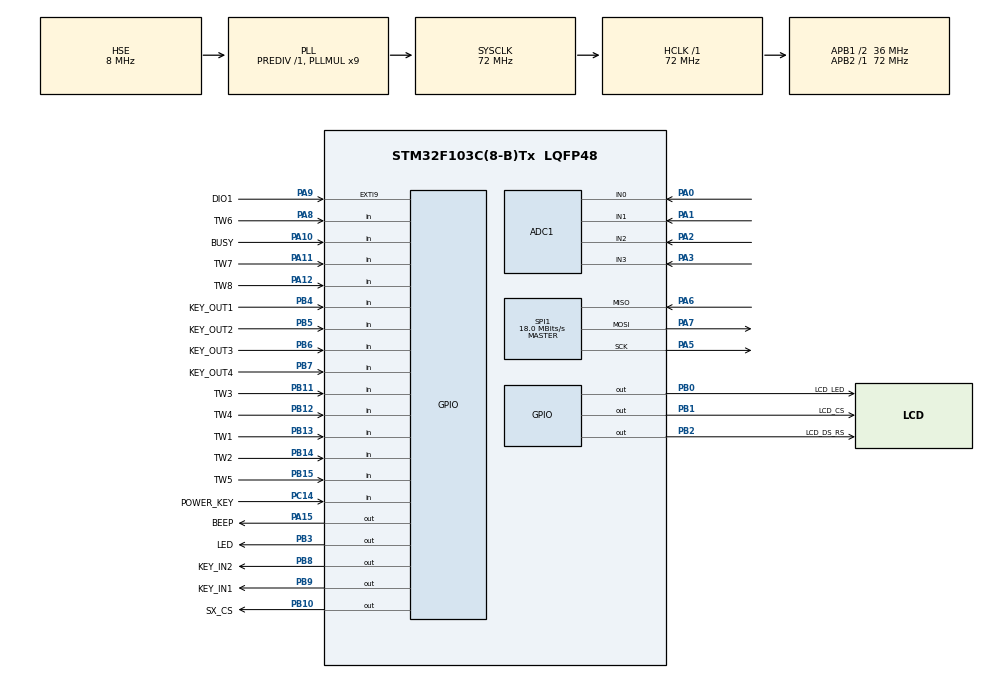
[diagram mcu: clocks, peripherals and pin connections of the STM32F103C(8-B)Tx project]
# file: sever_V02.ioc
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ADC1.Channel-1\#ChannelRegularConversion=ADC_CHANNEL_1
ADC1.Channel-2\#ChannelRegularConversion=ADC_CHANNEL_2
ADC1.Channel-3\#ChannelRegularConversion=ADC_CHANNEL_3
ADC1.ContinuousConvMode=ENABLE
ADC1.NbrOfConversion=4
ADC1.NbrOfConversionFlag=1
ADC1.Rank-1\#ChannelRegularConversion=2
ADC1.Rank-2\#ChannelRegularConversion=3
ADC1.Rank-3\#ChannelRegularConversion=4
ADC1.SamplingTime-0\#ChannelRegularConversion=ADC_SAMPLETIME_239CYCLES_5
ADC1.SamplingTime-1\#ChannelRegularConversion=ADC_SAMPLETIME_239CYCLES_5
ADC1.SamplingTime-2\#ChannelRegularConversion=ADC_SAMPLETIME_239CYCLES_5
ADC1.SamplingTime-3\#ChannelRegularConversion=ADC_SAMPLETIME_239CYCLES_5
ADC1.master=1
Dma.ADC1.0.Direction=DMA_PERIPH_TO_MEMORY
Dma.ADC1.0.Instance=DMA1_Channel1
Dma.ADC1.0.MemDataAlignment=DMA_MDATAALIGN_HALFWORD
Dma.ADC1.0.MemInc=DMA_MINC_ENABLE
Dma.ADC1.0.Mode=DMA_CIRCULAR
Dma.ADC1.0.PeriphDataAlignment=DMA_PDATAALIGN_HALFWORD
Dma.ADC1.0.PeriphInc=DMA_PINC_DISABLE
Dma.ADC1.0.Priority=DMA_PRIORITY_LOW
Dma.Request0=ADC1
FREERTOS.INCLUDE_uxTaskGetStackHighWaterMark=1
FREERTOS.INCLUDE_vTaskDelayUntil=1
FREERTOS.Tasks01=defaultTask,0,128,StartDefaultTask,Default,NULL,Dynamic,NULL,NULL;START_TASK,-3,128,startTask,Default,NULL,Dynamic,NULL,NULL
FREERTOS.configTOTAL_HEAP_SIZE=8192
FREERTOS.configUSE_COUNTING_SEMAPHORES=1
FREERTOS.configUSE_RECURSIVE_MUTEXES=1
Mcu.Family=STM32F1
Mcu.Name=STM32F103C(8-B)Tx
Mcu.Package=LQFP48
NVIC.DMA1_Channel1_IRQn=true\:5\:0\:false\:false\:true\:true\:false\:true\:true
NVIC.EXTI9_5_IRQn=true\:5\:0\:false\:false\:true\:true\:true\:true\:true
NVIC.PriorityGroup=NVIC_PRIORITYGROUP_4
NVIC.TIM3_IRQn=true\:15\:0\:false\:false\:true\:false\:false\:true\:true
NVIC.TIM4_IRQn=true\:5\:0\:false\:false\:true\:true\:true\:true\:true
NVIC.TimeBase=TIM3_IRQn
NVIC.TimeBaseIP=TIM3
PA0-WKUP.Signal=ADCx_IN0
PA1.Signal=ADCx_IN1
PA10.GPIO_Label=BUSY
PA10.GPIO_PuPd=GPIO_PULLUP
PA10.Signal=GPIO_Input
PA11.GPIO_Label=TW7
PA11.GPIO_PuPd=GPIO_PULLDOWN
PA11.Signal=GPIO_Input
PA12.GPIO_Label=TW8
PA12.GPIO_PuPd=GPIO_PULLDOWN
PA12.Signal=GPIO_Input
PA13.Mode=Serial_Wire
PA13.Signal=SYS_JTMS-SWDIO
PA14.Mode=Serial_Wire
PA14.Signal=SYS_JTCK-SWCLK
PA15.GPIO_Label=BEEP
PA15.Signal=GPIO_Output
PA2.Signal=ADCx_IN2
PA3.Signal=ADCx_IN3
PA5.Mode=Full_Duplex_Master
PA5.Signal=SPI1_SCK
PA6.Mode=Full_Duplex_Master
PA6.Signal=SPI1_MISO
PA7.Mode=Full_Duplex_Master
PA7.Signal=SPI1_MOSI
PA8.GPIO_Label=TW6
PA8.GPIO_PuPd=GPIO_PULLDOWN
PA8.Signal=GPIO_Input
PA9.GPIO_Label=DIO1
PA9.GPIO_PuPd=GPIO_PULLDOWN
PA9.Signal=GPXTI9
PB0.GPIO_Label=LCD_LED
PB0.Signal=GPIO_Output
PB1.GPIO_Label=LCD_CS
PB1.GPIO_Speed=GPIO_SPEED_FREQ_HIGH
PB1.PinState=GPIO_PIN_SET
PB1.Signal=GPIO_Output
PB10.GPIO_Label=SX_CS
PB10.GPIO_Speed=GPIO_SPEED_FREQ_HIGH
PB10.PinState=GPIO_PIN_SET
PB10.Signal=GPIO_Output
PB11.GPIO_Label=TW3
PB11.GPIO_PuPd=GPIO_PULLDOWN
PB11.Signal=GPIO_Input
PB12.GPIO_Label=TW4
PB12.GPIO_PuPd=GPIO_PULLDOWN
PB12.Signal=GPIO_Input
PB13.GPIO_Label=TW1
PB13.GPIO_PuPd=GPIO_PULLDOWN
PB13.Signal=GPIO_Input
PB14.GPIO_Label=TW2
PB14.GPIO_PuPd=GPIO_PULLDOWN
PB14.Signal=GPIO_Input
PB15.GPIO_Label=TW5
PB15.GPIO_PuPd=GPIO_PULLDOWN
PB15.Signal=GPIO_Input
PB2.GPIO_Label=LCD_DS_RS
PB2.Signal=GPIO_Output
PB3.GPIO_Label=LED
PB3.Signal=GPIO_Output
PB4.GPIO_Label=KEY_OUT1
PB4.GPIO_PuPd=GPIO_PULLDOWN
PB4.Signal=GPIO_Input
PB5.GPIO_Label=KEY_OUT2
PB5.GPIO_PuPd=GPIO_PULLDOWN
PB5.Signal=GPIO_Input
PB6.GPIO_Label=KEY_OUT3
PB6.GPIO_PuPd=GPIO_PULLDOWN
PB6.Signal=GPIO_Input
PB7.GPIO_Label=KEY_OUT4
PB7.GPIO_PuPd=GPIO_PULLDOWN
PB7.Signal=GPIO_Input
PB8.GPIO_Label=KEY_IN2
PB8.PinState=GPIO_PIN_RESET
PB8.Signal=GPIO_Output
PB9.GPIO_Label=KEY_IN1
PB9.PinState=GPIO_PIN_RESET
PB9.Signal=GPIO_Output
PC14-OSC32_IN.GPIO_Label=POWER_KEY
PC14-OSC32_IN.GPIO_PuPd=GPIO_PULLDOWN
PC14-OSC32_IN.Signal=GPIO_Input
PD0-OSC_IN.Mode=HSE-External-Oscillator
PD0-OSC_IN.Signal=RCC_OSC_IN
PD1-OSC_OUT.Mode=HSE-External-Oscillator
PD1-OSC_OUT.Signal=RCC_OSC_OUT
ProjectManager.HeapSize=0x200
ProjectManager.StackSize=0x400
ProjectManager.TargetToolchain=MDK-ARM V5.32
RCC.ADCPresc=RCC_ADCPCLK2_DIV6
RCC.AHBFreq_Value=72000000
RCC.APB1CLKDivider=RCC_HCLK_DIV2
RCC.APB1Freq_Value=36000000
RCC.APB1TimFreq_Value=72000000
RCC.APB2Freq_Value=72000000
RCC.APB2TimFreq_Value=72000000
RCC.HCLKFreq_Value=72000000
RCC.PLLMUL=RCC_PLL_MUL9
RCC.PLLSourceVirtual=RCC_PLLSOURCE_HSE
RCC.SYSCLKFreq_VALUE=72000000
RCC.SYSCLKSource=RCC_SYSCLKSOURCE_PLLCLK
RCC.USBFreq_Value=72000000
SH.ADCx_IN0.0=ADC1_IN0,IN0
SH.ADCx_IN1.0=ADC1_IN1,IN1
SH.ADCx_IN2.0=ADC1_IN2,IN2
SH.ADCx_IN3.0=ADC1_IN3,IN3
SPI1.BaudRatePrescaler=SPI_BAUDRATEPRESCALER_4
SPI1.CalculateBaudRate=18.0 MBits/s
SPI1.Direction=SPI_DIRECTION_2LINES
SPI1.Mode=SPI_MODE_MASTER
SPI1.VirtualType=VM_MASTER
TIM4.AutoReloadPreload=TIM_AUTORELOAD_PRELOAD_ENABLE
TIM4.Period=9
TIM4.Prescaler=8399
VP_FREERTOS_VS_CMSIS_V1.Mode=CMSIS_V1
VP_SYS_VS_tim3.Mode=TIM3
VP_TIM4_VS_ClockSourceINT.Mode=Internal
board=custom

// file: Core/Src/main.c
/* USER CODE BEGIN Header */
/**
  ******************************************************************************
  * @file           : main.c
  * @brief          : Main program body
  ******************************************************************************
  * @attention
  *
  * Copyright (c) 2026 STMicroelectronics.
  * All rights reserved.
  *
  * This software is licensed under terms that can be found in the LICENSE file
  * in the root directory of this software component.
  * If no LICENSE file comes with this software, it is provided AS-IS.
  *
  ******************************************************************************
  */
/* USER CODE END Header */
#include "main.h"
#include "cmsis_os.h"
#include "adc.h"
#include "dma.h"
#include "spi.h"
#include "tim.h"
#include "gpio.h"

/* USER CODE BEGIN Includes */
#include "global.h"
/* USER CODE END Includes */

void SystemClock_Config(void);
void MX_FREERTOS_Init(void);

int main(void)
{

  /* MCU Configuration--------------------------------------------------------*/

  /* Reset of all peripherals, Initializes the Flash interface and the Systick. */
  HAL_Init();

  /* Configure the system clock */
  SystemClock_Config();

  /* Initialize all configured peripherals */
  MX_GPIO_Init();
  MX_DMA_Init();
  MX_ADC1_Init();
  MX_SPI1_Init();
  MX_TIM4_Init();
  /* USER CODE BEGIN 2 */
	//HAL_GPIO_WritePin(BEEP_GPIO_Port, BEEP_Pin, GPIO_PIN_RESET);
	HAL_GPIO_WritePin(LED_GPIO_Port, LED_Pin, GPIO_PIN_SET);
  /* USER CODE END 2 */

  /* Call init function for freertos objects (in cmsis_os2.c) */
  MX_FREERTOS_Init();

  /* Start scheduler */
  osKernelStart();

  /* We should never get here as control is now taken by the scheduler */

  /* Infinite loop */
  while (1)
  {

  }
}

void SystemClock_Config(void)
{
  RCC_OscInitTypeDef RCC_OscInitStruct = {0};
  RCC_ClkInitTypeDef RCC_ClkInitStruct = {0};
  RCC_PeriphCLKInitTypeDef PeriphClkInit = {0};

  /** Initializes the RCC Oscillators according to the specified parameters
  * in the RCC_OscInitTypeDef structure.
  */
  RCC_OscInitStruct.OscillatorType = RCC_OSCILLATORTYPE_HSE;
  RCC_OscInitStruct.HSEState = RCC_HSE_ON;
  RCC_OscInitStruct.HSEPredivValue = RCC_HSE_PREDIV_DIV1;
  RCC_OscInitStruct.HSIState = RCC_HSI_ON;
  RCC_OscInitStruct.PLL.PLLState = RCC_PLL_ON;
  RCC_OscInitStruct.PLL.PLLSource = RCC_PLLSOURCE_HSE;
  RCC_OscInitStruct.PLL.PLLMUL = RCC_PLL_MUL9;
  if (HAL_RCC_OscConfig(&RCC_OscInitStruct) != HAL_OK)
  {
    Error_Handler();
  }

  /** Initializes the CPU, AHB and APB buses clocks
  */
  RCC_ClkInitStruct.ClockType = RCC_CLOCKTYPE_HCLK|RCC_CLOCKTYPE_SYSCLK
                              |RCC_CLOCKTYPE_PCLK1|RCC_CLOCKTYPE_PCLK2;
  RCC_ClkInitStruct.SYSCLKSource = RCC_SYSCLKSOURCE_PLLCLK;
  RCC_ClkInitStruct.AHBCLKDivider = RCC_SYSCLK_DIV1;
  RCC_ClkInitStruct.APB1CLKDivider = RCC_HCLK_DIV2;
  RCC_ClkInitStruct.APB2CLKDivider = RCC_HCLK_DIV1;

  if (HAL_RCC_ClockConfig(&RCC_ClkInitStruct, FLASH_LATENCY_2) != HAL_OK)
  {
    Error_Handler();
  }
  PeriphClkInit.PeriphClockSelection = RCC_PERIPHCLK_ADC;
  PeriphClkInit.AdcClockSelection = RCC_ADCPCLK2_DIV6;
  if (HAL_RCCEx_PeriphCLKConfig(&PeriphClkInit) != HAL_OK)
  {
    Error_Handler();
  }
}

void HAL_TIM_PeriodElapsedCallback(TIM_HandleTypeDef *htim)
{
  if (htim->Instance == TIM3)
  {
    HAL_IncTick();
  }
}

void Error_Handler(void)
{
  __disable_irq();
  while (1)
  {
  }
}

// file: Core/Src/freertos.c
/* USER CODE BEGIN Header */
/**
  ******************************************************************************
  * File Name          : freertos.c
  * Description        : Code for freertos applications
  ******************************************************************************
  * @attention
  *
  * Copyright (c) 2026 STMicroelectronics.
  * All rights reserved.
  *
  * This software is licensed under terms that can be found in the LICENSE file
  * in the root directory of this software component.
  * If no LICENSE file comes with this software, it is provided AS-IS.
  *
  ******************************************************************************
  */
/* USER CODE END Header */

#include "FreeRTOS.h"
#include "task.h"
#include "main.h"
#include "cmsis_os.h"

/* USER CODE BEGIN Includes */
#include "global.h"
/* USER CODE END Includes */

/* USER CODE BEGIN PTD */
xQueueHandle rcctrlDataQueue;
xQueueHandle controlcommandDataQueue;
xQueueHandle rccontrolDataQueue;
/* USER CODE END PTD */

osThreadId defaultTaskHandle;
osThreadId START_TASKHandle;

void StartDefaultTask(void const * argument);
void startTask(void const * argument);

void MX_FREERTOS_Init(void); /* (MISRA C 2004 rule 8.1) */

/* GetIdleTaskMemory prototype (linked to static allocation support) */
void vApplicationGetIdleTaskMemory( StaticTask_t **ppxIdleTaskTCBBuffer, StackType_t **ppxIdleTaskStackBuffer, uint32_t *pulIdleTaskStackSize );

/* USER CODE BEGIN GET_IDLE_TASK_MEMORY */
static StaticTask_t xIdleTaskTCBBuffer;
static StackType_t xIdleStack[configMINIMAL_STACK_SIZE];

void vApplicationGetIdleTaskMemory( StaticTask_t **ppxIdleTaskTCBBuffer, StackType_t **ppxIdleTaskStackBuffer, uint32_t *pulIdleTaskStackSize )
{
  *ppxIdleTaskTCBBuffer = &xIdleTaskTCBBuffer;
  *ppxIdleTaskStackBuffer = &xIdleStack[0];
  *pulIdleTaskStackSize = configMINIMAL_STACK_SIZE;
  /* place for user code */
}
/* USER CODE END GET_IDLE_TASK_MEMORY */

void MX_FREERTOS_Init(void) {
  /* USER CODE BEGIN Init */
	rcctrlDataQueue = xQueueCreate(1, sizeof(rc_ctrl_t));
	controlcommandDataQueue = xQueueCreate(1, sizeof(control_command_t));
	rccontrolDataQueue = xQueueCreate(1, sizeof(rc_control_command_t));
  /* USER CODE END Init */

  /* Create the thread(s) */
  /* definition and creation of defaultTask */
  osThreadDef(defaultTask, StartDefaultTask, osPriorityNormal, 0, 128);
  defaultTaskHandle = osThreadCreate(osThread(defaultTask), NULL);

  /* definition and creation of START_TASK */
  osThreadDef(START_TASK, startTask, osPriorityIdle, 0, 128);
  START_TASKHandle = osThreadCreate(osThread(START_TASK), NULL);

}

void StartDefaultTask(void const * argument)
{
  for(;;)
  {
    osDelay(1);
  }
}

void startTask(void const * argument)
{
  /* USER CODE BEGIN startTask */
	xTaskCreate(updateStateTask, "UPDATESTATETASK", 100, NULL, 4, NULL);
  xTaskCreate(wirelessTxTask, "WIRELESSTXTASK", 100, NULL, 5, NULL);
  //xTaskCreate(wirelessRxTask, "WIRELESSRXTASK", 10, NULL, 5, NULL);
	xTaskCreate(wirelessTask, "WIRELESSTASK", 100, NULL, 6, NULL);
	//xTaskCreate(lcdTask, "LCDTASK", 200, NULL, 3, NULL);
	vTaskDelete(NULL);
  /* Infinite loop */
  for(;;)
  {
    osDelay(1);
  }
  /* USER CODE END startTask */
}
